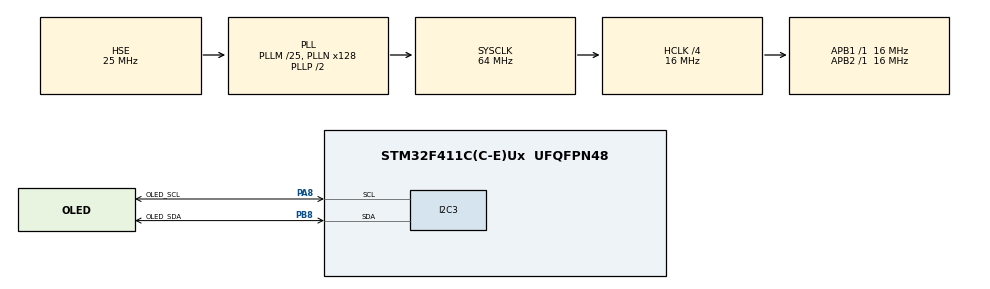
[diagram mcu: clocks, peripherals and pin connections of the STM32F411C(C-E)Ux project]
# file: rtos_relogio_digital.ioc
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FREERTOS.Queues01=oledQueue,16,RTC_TimeTypeDef,0,Dynamic,NULL,NULL
FREERTOS.Tasks01=rtcTask,24,128,RtcTask,Default,NULL,Dynamic,NULL,NULL;oledTask,8,128,OledTask,Default,NULL,Dynamic,NULL,NULL
FREERTOS.configUSE_NEWLIB_REENTRANT=1
Mcu.Family=STM32F4
Mcu.Name=STM32F411C(C-E)Ux
Mcu.Package=UFQFPN48
NVIC.PriorityGroup=NVIC_PRIORITYGROUP_4
NVIC.TIM2_IRQn=true\:15\:0\:false\:false\:true\:false\:false\:true\:true
NVIC.TimeBase=TIM2_IRQn
NVIC.TimeBaseIP=TIM2
PA13.Mode=Serial_Wire
PA13.Signal=SYS_JTMS-SWDIO
PA14.Mode=Serial_Wire
PA14.Signal=SYS_JTCK-SWCLK
PA8.GPIO_Label=OLED_SCL
PA8.Mode=I2C
PA8.Signal=I2C3_SCL
PB8.GPIO_Label=OLED_SDA
PB8.Mode=I2C
PB8.Signal=I2C3_SDA
PC14-OSC32_IN.Mode=LSE-External-Oscillator
PC14-OSC32_IN.Signal=RCC_OSC32_IN
PC15-OSC32_OUT.Mode=LSE-External-Oscillator
PC15-OSC32_OUT.Signal=RCC_OSC32_OUT
PH0\ -\ OSC_IN.Mode=HSE-External-Oscillator
PH0\ -\ OSC_IN.Signal=RCC_OSC_IN
PH1\ -\ OSC_OUT.Mode=HSE-External-Oscillator
PH1\ -\ OSC_OUT.Signal=RCC_OSC_OUT
ProjectManager.HeapSize=0x200
ProjectManager.StackSize=0x400
ProjectManager.TargetToolchain=STM32CubeIDE
RCC.48MHZClocksFreq_Value=32000000
RCC.AHBCLKDivider=RCC_SYSCLK_DIV4
RCC.AHBFreq_Value=16000000
RCC.APB1Freq_Value=16000000
RCC.APB1TimFreq_Value=16000000
RCC.APB2Freq_Value=16000000
RCC.APB2TimFreq_Value=16000000
RCC.CortexFreq_Value=16000000
RCC.HCLKFreq_Value=16000000
RCC.HSE_VALUE=25000000
RCC.HSI_VALUE=16000000
RCC.PLLM=25
RCC.PLLN=128
RCC.PLLSourceVirtual=RCC_PLLSOURCE_HSE
RCC.RCC_RTC_Clock_Source=RCC_RTCCLKSOURCE_LSE
RCC.SYSCLKFreq_VALUE=64000000
RCC.SYSCLKSource=RCC_SYSCLKSOURCE_PLLCLK
RCC.VCOOutputFreq_Value=128000000
VP_FREERTOS_VS_CMSIS_V2.Mode=CMSIS_V2
VP_RTC_VS_RTC_Activate.Mode=RTC_Enabled
VP_SYS_VS_tim2.Mode=TIM2
board=custom

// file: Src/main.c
/* USER CODE BEGIN Header */
/**
  ******************************************************************************
  * @file           : main.c
  * @brief          : Main program body
  ******************************************************************************
  * @attention
  *
  * Copyright (c) 2026 STMicroelectronics.
  * All rights reserved.
  *
  * This software is licensed under terms that can be found in the LICENSE file
  * in the root directory of this software component.
  * If no LICENSE file comes with this software, it is provided AS-IS.
  *
  ******************************************************************************
  */
/* USER CODE END Header */
#include "main.h"
#include "cmsis_os.h"
#include "i2c.h"
#include "rtc.h"
#include "gpio.h"

/* USER CODE BEGIN Includes */
#include "ssd1306.h"
/* USER CODE END Includes */

void SystemClock_Config(void);
void MX_FREERTOS_Init(void);

int main(void)
{

  /* MCU Configuration--------------------------------------------------------*/

  /* Reset of all peripherals, Initializes the Flash interface and the Systick. */
  HAL_Init();

  /* Configure the system clock */
  SystemClock_Config();

  /* Initialize all configured peripherals */
  MX_GPIO_Init();
  MX_I2C3_Init();
  MX_RTC_Init();

  /* Init scheduler */
  osKernelInitialize();  /* Call init function for freertos objects (in cmsis_os2.c) */
  MX_FREERTOS_Init();

  /* Start scheduler */
  osKernelStart();

  /* We should never get here as control is now taken by the scheduler */

  /* Infinite loop */
  while (1)
  {

  }
}

void SystemClock_Config(void)
{
  RCC_OscInitTypeDef RCC_OscInitStruct = {0};
  RCC_ClkInitTypeDef RCC_ClkInitStruct = {0};

  /** Configure the main internal regulator output voltage
  */
  __HAL_RCC_PWR_CLK_ENABLE();
  __HAL_PWR_VOLTAGESCALING_CONFIG(PWR_REGULATOR_VOLTAGE_SCALE1);

  /** Initializes the RCC Oscillators according to the specified parameters
  * in the RCC_OscInitTypeDef structure.
  */
  RCC_OscInitStruct.OscillatorType = RCC_OSCILLATORTYPE_HSE|RCC_OSCILLATORTYPE_LSE;
  RCC_OscInitStruct.HSEState = RCC_HSE_ON;
  RCC_OscInitStruct.LSEState = RCC_LSE_ON;
  RCC_OscInitStruct.PLL.PLLState = RCC_PLL_ON;
  RCC_OscInitStruct.PLL.PLLSource = RCC_PLLSOURCE_HSE;
  RCC_OscInitStruct.PLL.PLLM = 25;
  RCC_OscInitStruct.PLL.PLLN = 128;
  RCC_OscInitStruct.PLL.PLLP = RCC_PLLP_DIV2;
  RCC_OscInitStruct.PLL.PLLQ = 4;
  if (HAL_RCC_OscConfig(&RCC_OscInitStruct) != HAL_OK)
  {
    Error_Handler();
  }

  /** Initializes the CPU, AHB and APB buses clocks
  */
  RCC_ClkInitStruct.ClockType = RCC_CLOCKTYPE_HCLK|RCC_CLOCKTYPE_SYSCLK
                              |RCC_CLOCKTYPE_PCLK1|RCC_CLOCKTYPE_PCLK2;
  RCC_ClkInitStruct.SYSCLKSource = RCC_SYSCLKSOURCE_PLLCLK;
  RCC_ClkInitStruct.AHBCLKDivider = RCC_SYSCLK_DIV4;
  RCC_ClkInitStruct.APB1CLKDivider = RCC_HCLK_DIV1;
  RCC_ClkInitStruct.APB2CLKDivider = RCC_HCLK_DIV1;

  if (HAL_RCC_ClockConfig(&RCC_ClkInitStruct, FLASH_LATENCY_0) != HAL_OK)
  {
    Error_Handler();
  }
}

void HAL_TIM_PeriodElapsedCallback(TIM_HandleTypeDef *htim)
{
  if (htim->Instance == TIM2)
  {
    HAL_IncTick();
  }
}

void Error_Handler(void)
{
  __disable_irq();
  while (1)
  {
  }
}

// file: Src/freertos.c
/* USER CODE BEGIN Header */
/**
  ******************************************************************************
  * @file freertos.c
  * @brief Implementação das tarefas RTOS para leitura do RTC e exibição em display OLED.
  * @author Wu Shin Ting
  * @date 21/03/2026
  ******************************************************************************
  * @attention
  *
  * Copyright (c) 2026 STMicroelectronics.
  * All rights reserved.
  *
  * This software is licensed under terms that can be found in the LICENSE file
  * in the root directory of this software component.
  * If no LICENSE file comes with this software, it is provided AS-IS.
  *
  ******************************************************************************
  * @section overview Visão Geral
  *
  * Este arquivo contém a implementação da lógica concorrente do sistema utilizando
  * CMSIS-RTOS v2 sobre FreeRTOS. O objetivo principal é ler periodicamente o tempo
  * do RTC (Real-Time Clock) e exibi-lo em um display OLED baseado no controlador SSD1306.
  *
  * A arquitetura é baseada em tarefas independentes que se comunicam por meio de
  * uma fila RTOS, promovendo desacoplamento entre aquisição de dados (RTC) e
  * apresentação (display).
  *
  * @section user_code Código Implementado Manualmente
  *
  * Os principais elementos implementados manualmente neste arquivo incluem:
  *
  * - Criação e configuração das tarefas:
  *   - @c RtcTask: responsável pela leitura periódica do RTC
  *   - @c OledTask: responsável pela atualização do display OLED
  *
  * - Criação da fila RTOS:
  *   - @c oledQueueHandle: utilizada para transferir estruturas de tempo (@c RTC_TimeTypeDef)
  *     entre as tarefas
  *
  * - Implementação da lógica das tasks:
  *   - Inicialização do RTC (tempo inicial)
  *   - Leitura contínua do tempo
  *   - Formatação da string de horário
  *   - Atualização do display via driver SSD1306
  *
  * - Integração com drivers:
  *   - RTC (HAL)
  *   - I2C
  *   - Display OLED (SSD1306)
  *
  * @section mental_model Modelo Mental do Sistema
  *
  * O sistema pode ser interpretado como um pipeline produtor-consumidor:
  *
  * @code
  *        RtcTask (produtor)
  *              │
  *              ├── HAL_RTC_GetTime()
  *              ├── HAL_RTC_GetDate()
  *              ▼
  *         oledQueue (fila RTOS)
  *              ▼
  *        OledTask (consumidor)
  *              ├── formatação HH:MM:SS
  *              ├── renderização gráfica
  *              ▼
  *        Display OLED (SSD1306 via I2C)
  * @endcode
  *
  * Fluxo de execução:
  * - A RtcTask lê o tempo atual a cada 500 ms
  * - Envia os dados para a fila
  * - A OledTask bloqueia aguardando novos dados
  * - Ao receber, atualiza completamente o display
  *
  * Características do modelo:
  * - Tasks bloqueantes (sem polling)
  * - Comunicação assíncrona via fila
  * - Separação clara entre aquisição e interface gráfica
  *
  *
  * @section cube_config Configuração no CubeMX
  *
  * A configuração de hardware foi realizada no STM32CubeMX com os seguintes pontos:
  *
  * - RTC:
  *   - Utiliza fonte de clock LSE (Low-Speed External), garantindo maior precisão
  *     para contagem de tempo
  *
  * - Sistema:
  *   - Utiliza HSE (High-Speed External) como fonte principal de clock para o restante
  *     dos periféricos e do núcleo
  *
  * - I2C:
  *   - Configurado para comunicação com o display OLED SSD1306
  *
  * - FreeRTOS:
  *   - Duas tarefas configuradas (RTC e OLED)
  *   - Uma fila para comunicação entre tasks
  *
  * @note
  * Neste projeto, o arquivo @c main.c gerado pelo CubeMX não foi modificado.
  * Toda a lógica adicional foi implementada exclusivamente neste arquivo (@c freertos.c),
  * mantendo a separação entre código gerado automaticamente e código de aplicação.
  *
  * @warning
  * - A função @c HAL_RTC_GetDate() deve ser chamada após @c HAL_RTC_GetTime()
  *   para garantir leitura correta no STM32F4
  * - A atualização completa do display a cada ciclo pode impactar desempenho
  *   em aplicações mais complexas
*/
/* USER CODE END Header */

#include "FreeRTOS.h"
#include "task.h"
#include "main.h"
#include "cmsis_os.h"

/* USER CODE BEGIN Includes */
#include "i2c.h"
#include "rtc.h"
#include "ssd1306.h"
#include "ssd1306_fonts.h"
#include "conversions.h"
/* USER CODE END Includes */

/* Definitions for rtcTask */
osThreadId_t rtcTaskHandle;
const osThreadAttr_t rtcTask_attributes = {
  .name = "rtcTask",
  .stack_size = 128 * 4,
  .priority = (osPriority_t) osPriorityNormal,
};
/* Definitions for oledTask */
osThreadId_t oledTaskHandle;
const osThreadAttr_t oledTask_attributes = {
  .name = "oledTask",
  .stack_size = 128 * 4,
  .priority = (osPriority_t) osPriorityLow,
};
/* Definitions for oledQueue */
osMessageQueueId_t oledQueueHandle;
const osMessageQueueAttr_t oledQueue_attributes = {
  .name = "oledQueue"
};

void RtcTask(void *argument);
void OledTask(void *argument);

void MX_FREERTOS_Init(void); /* (MISRA C 2004 rule 8.1) */

void MX_FREERTOS_Init(void) {

  /* Create the queue(s) */
  /* creation of oledQueue */
  oledQueueHandle = osMessageQueueNew (16, sizeof(RTC_TimeTypeDef), &oledQueue_attributes);

  /* Create the thread(s) */
  /* creation of rtcTask */
  rtcTaskHandle = osThreadNew(RtcTask, NULL, &rtcTask_attributes);

  /* creation of oledTask */
  oledTaskHandle = osThreadNew(OledTask, NULL, &oledTask_attributes);

}

/* USER CODE BEGIN Header_RtcTask */
/**
 * @brief Task responsável pela leitura periódica do RTC (Real-Time Clock).
 *
 * @details
 * Esta função implementa uma task do FreeRTOS, ou seja, uma "função que roda
 * em paralelo" com outras partes do sistema. No contexto de RTOS, cada task
 * executa de forma independente e pode ser escalonada pelo sistema operacional.
 *
 * O objetivo desta task é:
 * - Configurar um horário inicial no RTC
 * - Ler continuamente o horário atual
 * - Enviar esse horário para outra task (OledTask) através de uma fila
 *
 * Funcionamento passo a passo:
 *
 * 1. Inicialização do tempo:
 *    - Define um horário inicial (17:58:55)
 *    - Configura o RTC com esse valor usando @c HAL_RTC_SetTime()
 *
 * 2. Loop infinito:
 *    - Toda task RTOS normalmente possui um loop infinito (@c for(;;))
 *    - Dentro desse loop, a task executa sua função continuamente
 *
 * 3. Leitura do RTC:
 *    - @c HAL_RTC_GetTime(): lê o horário atual
 *    - @c HAL_RTC_GetDate(): necessário para "validar" a leitura no STM32F4
 *
 * 4. Comunicação entre tasks:
 *    - O horário lido é enviado para a fila @c oledQueueHandle
 *    - Outra task (OledTask) irá receber esses dados e atualizar o display
 *
 * 5. Delay controlado:
 *    - @c osDelay(500) faz a task "dormir" por 500 ms
 *    - Isso evita uso excessivo da CPU e define a taxa de atualização
 *
 * Conceitos importantes:
 *
 * - Task:
 *   Uma função executada pelo RTOS de forma concorrente com outras tasks.
 *
 * - Fila (Queue):
 *   Mecanismo seguro para troca de dados entre tasks.
 *
 * - Bloqueio (Delay):
 *   Ao usar @c osDelay(), a task libera a CPU para outras tasks.
 *
 * @param argument Parâmetro da task (não utilizado)
 * @retval None
 *
 * @note
 * - A chamada de @c HAL_RTC_GetDate() após @c HAL_RTC_GetTime() é obrigatória
 *   em microcontroladores STM32F4 para garantir leitura correta
 * - O envio para a fila é não bloqueante (timeout = 0)
 *
 * @warning
 * - Se a fila estiver cheia, o dado pode ser perdido (não há tratamento de erro)
 * - O tempo é reinicializado sempre que o sistema inicia
 *
 * @see OledTask
 * @see osMessageQueuePut
 */
/* USER CODE END Header_RtcTask */
void RtcTask(void *argument)
{
	/* USER CODE BEGIN RtcTask */
	/* Configurar o tempo inicial */
	RTC_TimeTypeDef sTime = {0};
	RTC_DateTypeDef sDate = {0}; // Necessário para a leitura correta no F4

	/* Definir o tempo inicial: 17:58:55 */
	sTime.Hours = 17;
	sTime.Minutes = 58;
	sTime.Seconds = 55;
	sTime.DayLightSaving = RTC_DAYLIGHTSAVING_NONE;
	sTime.StoreOperation = RTC_STOREOPERATION_RESET;

	if (HAL_RTC_SetTime(&hrtc, &sTime, RTC_FORMAT_BIN) != HAL_OK)
	{
		Error_Handler();
	}

	/* Infinite loop */
	for(;;)
	{
		/*Obter o tempo e data correntes  */
		HAL_RTC_GetTime(&hrtc, &sTime, RTC_FORMAT_BIN);
		HAL_RTC_GetDate(&hrtc, &sDate, RTC_FORMAT_BIN); // Important: Must call GetDate after GetTime

		(void)osMessageQueuePut(oledQueueHandle, &sTime, 0U, 0U);

		osDelay(500);
	}
	/* USER CODE END RtcTask */
}

/* USER CODE BEGIN Header_OledTask */
/**
 * @brief Task responsável por exibir o horário no display OLED.
 *
 * @details
 * Esta função implementa uma task do FreeRTOS que atua como consumidora
 * no modelo produtor-consumidor. Sua função é receber o horário atual
 * (enviado pela @c RtcTask) e exibi-lo em um display OLED.
 *
 * Funcionamento passo a passo:
 *
 * 1. Inicialização do display:
 *    - A função @c ssd1306_Init() configura o display OLED
 *    - Essa inicialização ocorre apenas uma vez, antes do loop infinito
 *
 * 2. Loop infinito:
 *    - Como toda task RTOS, utiliza @c for(;;) para execução contínua
 *
 * 3. Recebimento de dados:
 *    - @c osMessageQueueGet() aguarda dados da fila @c oledQueueHandle
 *    - A task fica BLOQUEADA até que novos dados estejam disponíveis
 *    - Isso evita uso desnecessário da CPU (sem polling)
 *
 * 4. Processamento dos dados:
 *    - Converte os valores de hora, minuto e segundo para string
 *      no formato "HH:MM:SS" usando @c format_time_hhmmss()
 *
 * 5. Atualização do display:
 *    - Limpa a tela (@c ssd1306_Fill)
 *    - Define a posição do cursor (@c ssd1306_SetCursor)
 *    - Escreve a string formatada (@c ssd1306_WriteString)
 *    - Atualiza fisicamente o display (@c ssd1306_UpdateScreen)
 *
 * Conceitos importantes para iniciantes:
 *
 * - Task consumidora:
 *   Recebe dados produzidos por outra task (RtcTask).
 *
 * - Fila (Queue):
 *   Utilizada para comunicação segura entre tasks.
 *
 * - Bloqueio eficiente:
 *   O uso de @c osWaitForever faz com que a task só execute quando necessário.
 *
 * - Atualização de display:
 *   A escrita no SSD1306 ocorre em memória interna e só aparece na tela após
 *   @c ssd1306_UpdateScreen().
 *
 * @param argument Parâmetro da task (não utilizado)
 * @retval None
 *
 * @note
 * - O buffer @c time_str deve ter tamanho suficiente para "HH:MM:SS" + terminador nulo
 * - A task só executa quando há novos dados na fila
 *
 * @warning
 * - Atualizações frequentes do display podem impactar desempenho em sistemas maiores
 * - Caso múltiplas tasks acessem o display, será necessário mecanismo de sincronização
 *
 * @see RtcTask
 * @see osMessageQueueGet
 * @see ssd1306_UpdateScreen
 */
/* USER CODE END Header_OledTask */
void OledTask(void *argument)
{
	RTC_TimeTypeDef sTime;
	char time_str[9]; /* "HH:MM:SS" */

	/* USER CODE BEGIN OledTask */
	/* Inicializa o driver SSD1306 para OLED */
	ssd1306_Init();

	/* Infinite loop */
	for(;;)
	{
		if (osMessageQueueGet(oledQueueHandle, &sTime, NULL, osWaitForever) == osOK) {
			/* Formatar os valores em HH:MM:SS  */
			format_time_hhmmss(sTime.Hours, sTime.Minutes, sTime.Seconds, time_str);

			/* Preecher a tela com a cor branca */
			ssd1306_Fill(White);

			/* Centralizar text (128x64) */
			ssd1306_SetCursor(32, 24);

			/* Escrever o texto em fonte 7x10 e cor preta */
			ssd1306_WriteString(time_str, Font_7x10, Black);

			/* Atualizar a tela */
			ssd1306_UpdateScreen();

		}
	}
	/* USER CODE END OledTask */
}
